AUTOSAR XML (schema 00051)
package /SwComponentTypes
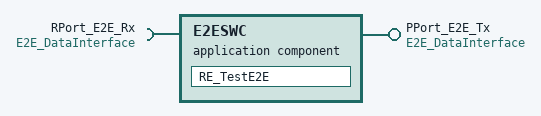
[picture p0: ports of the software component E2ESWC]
  application sw component type E2ESWC
    provide port PPort_E2E_Tx: provided-interface=E2E_DataInterface
    require port RPort_E2E_Rx: required-interface=E2E_DataInterface
    behavior SwcInternalBehavior
      data received event DRE_TestE2E: start-on-event=RE_TestE2E, data=RPort_E2E_Rx.Data
      runnable RE_TestE2E: symbol=RE_TestE2E_func
        data-receive-point-by-arguments:
          access DRPA_CKS_0: accessed-variable=RPort_E2E_Rx.CKS
          access DRPA_Alive_Cnt_0: accessed-variable=RPort_E2E_Rx.Alive_Cnt
          access DRPA_Data_0: accessed-variable=RPort_E2E_Rx.Data
        data-send-points:
          access DSP_CKS_0: accessed-variable=PPort_E2E_Tx.CKS
          access DSP_Alive_Cnt_0: accessed-variable=PPort_E2E_Tx.Alive_Cnt
          access DSP_Data_0: accessed-variable=PPort_E2E_Tx.Data
